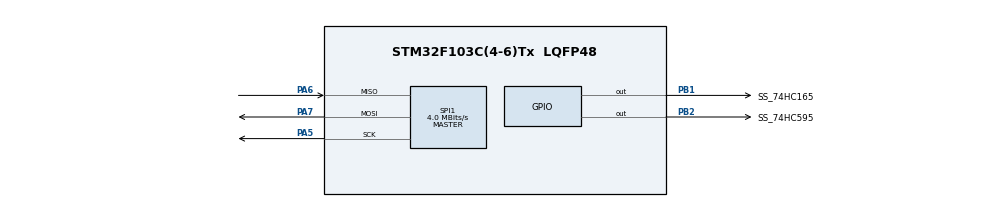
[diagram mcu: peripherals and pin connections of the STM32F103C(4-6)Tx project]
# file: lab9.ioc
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Mcu.Family=STM32F1
PA6.Mode=Full_Duplex_Master
RCC.APB2Freq_Value=8000000
PA7.Mode=Full_Duplex_Master
SPI1.Mode=SPI_MODE_MASTER
SPI1.VirtualType=VM_MASTER
PB1.GPIO_Label=SS_74HC165
Mcu.Name=STM32F103C(4-6)Tx
VP_SYS_VS_ND.Mode=No_Debug
Mcu.Package=LQFP48
PB1.Signal=GPIO_Output
PA6.Signal=SPI1_MISO
ProjectManager.StackSize=0x400
PB2.GPIO_Label=SS_74HC595
ProjectManager.HeapSize=0x200
ProjectManager.TargetToolchain=STM32CubeIDE
NVIC.PriorityGroup=NVIC_PRIORITYGROUP_4
SPI1.Direction=SPI_DIRECTION_2LINES
SPI1.CalculateBaudRate=4.0 MBits/s
RCC.APB1Freq_Value=8000000
PA5.Signal=SPI1_SCK
PB2.Signal=GPIO_Output
PA7.Signal=SPI1_MOSI
PA5.Mode=Full_Duplex_Master
board=custom

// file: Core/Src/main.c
/* USER CODE BEGIN Header */
/**
  ******************************************************************************
  * @file           : main.c
  * @brief          : Main program body
  ******************************************************************************
  * @attention
  *
  * <h2><center>&copy; Copyright (c) 2021 STMicroelectronics.
  * All rights reserved.</center></h2>
  *
  * This software component is licensed by ST under BSD 3-Clause license,
  * the "License"; You may not use this file except in compliance with the
  * License. You may obtain a copy of the License at:
  *                        opensource.org/licenses/BSD-3-Clause
  *
  ******************************************************************************
  */
/* USER CODE END Header */
#include "main.h"

SPI_HandleTypeDef hspi1;

/* USER CODE BEGIN PV */
uint8_t spi_buf[2] = {0,0};
/* USER CODE END PV */

void SystemClock_Config(void);
static void MX_GPIO_Init(void);
static void MX_SPI1_Init(void);

int main(void)
{

  /* MCU Configuration--------------------------------------------------------*/

  /* Reset of all peripherals, Initializes the Flash interface and the Systick. */
  HAL_Init();

  /* Configure the system clock */
  SystemClock_Config();

  /* Initialize all configured peripherals */
  MX_GPIO_Init();
  MX_SPI1_Init();
  /* USER CODE BEGIN 2 */
  HAL_GPIO_WritePin(SS_74HC165_GPIO_Port, SS_74HC165_Pin, GPIO_PIN_SET);
  HAL_GPIO_WritePin(SS_74HC595_GPIO_Port, SS_74HC595_Pin, GPIO_PIN_SET);

  //HAL_SPI_Transmit(&hspi1, outputBuffer, 4, 100);
  //uint8_t inputBuffer[4];
  //HAL_SPI_Receive(&hspi1, inputBuffer, 4, 100);

  /* USER CODE END 2 */

  /* Infinite loop */
  while (1)
  {
	  HAL_GPIO_WritePin(SS_74HC165_GPIO_Port, SS_74HC165_Pin, GPIO_PIN_RESET);

	  HAL_GPIO_WritePin(SS_74HC165_GPIO_Port, SS_74HC165_Pin, GPIO_PIN_SET);
	  HAL_SPI_Receive(&hspi1, (uint8_t *)spi_buf, 2, 100);

	  HAL_GPIO_WritePin(SS_74HC595_GPIO_Port, SS_74HC595_Pin, GPIO_PIN_RESET);
	  HAL_SPI_Transmit(&hspi1, (uint8_t *)spi_buf, 2, 100);
	  HAL_GPIO_WritePin(SS_74HC595_GPIO_Port, SS_74HC595_Pin, GPIO_PIN_SET);
  }
}

void SystemClock_Config(void)
{
  RCC_OscInitTypeDef RCC_OscInitStruct = {0};
  RCC_ClkInitTypeDef RCC_ClkInitStruct = {0};

  /** Initializes the RCC Oscillators according to the specified parameters
  * in the RCC_OscInitTypeDef structure.
  */
  RCC_OscInitStruct.OscillatorType = RCC_OSCILLATORTYPE_HSI;
  RCC_OscInitStruct.HSIState = RCC_HSI_ON;
  RCC_OscInitStruct.HSICalibrationValue = RCC_HSICALIBRATION_DEFAULT;
  RCC_OscInitStruct.PLL.PLLState = RCC_PLL_NONE;
  if (HAL_RCC_OscConfig(&RCC_OscInitStruct) != HAL_OK)
  {
    Error_Handler();
  }
  /** Initializes the CPU, AHB and APB buses clocks
  */
  RCC_ClkInitStruct.ClockType = RCC_CLOCKTYPE_HCLK|RCC_CLOCKTYPE_SYSCLK
                              |RCC_CLOCKTYPE_PCLK1|RCC_CLOCKTYPE_PCLK2;
  RCC_ClkInitStruct.SYSCLKSource = RCC_SYSCLKSOURCE_HSI;
  RCC_ClkInitStruct.AHBCLKDivider = RCC_SYSCLK_DIV1;
  RCC_ClkInitStruct.APB1CLKDivider = RCC_HCLK_DIV1;
  RCC_ClkInitStruct.APB2CLKDivider = RCC_HCLK_DIV1;

  if (HAL_RCC_ClockConfig(&RCC_ClkInitStruct, FLASH_LATENCY_0) != HAL_OK)
  {
    Error_Handler();
  }
}

static void MX_SPI1_Init(void)
{

  /* SPI1 parameter configuration*/
  hspi1.Instance = SPI1;
  hspi1.Init.Mode = SPI_MODE_MASTER;
  hspi1.Init.Direction = SPI_DIRECTION_2LINES;
  hspi1.Init.DataSize = SPI_DATASIZE_8BIT;
  hspi1.Init.CLKPolarity = SPI_POLARITY_LOW;
  hspi1.Init.CLKPhase = SPI_PHASE_1EDGE;
  hspi1.Init.NSS = SPI_NSS_SOFT;
  hspi1.Init.BaudRatePrescaler = SPI_BAUDRATEPRESCALER_2;
  hspi1.Init.FirstBit = SPI_FIRSTBIT_MSB;
  hspi1.Init.TIMode = SPI_TIMODE_DISABLE;
  hspi1.Init.CRCCalculation = SPI_CRCCALCULATION_DISABLE;
  hspi1.Init.CRCPolynomial = 10;
  if (HAL_SPI_Init(&hspi1) != HAL_OK)
  {
    Error_Handler();
  }

}

static void MX_GPIO_Init(void)
{
  GPIO_InitTypeDef GPIO_InitStruct = {0};

  /* GPIO Ports Clock Enable */
  __HAL_RCC_GPIOA_CLK_ENABLE();
  __HAL_RCC_GPIOB_CLK_ENABLE();

  /*Configure GPIO pin Output Level */
  HAL_GPIO_WritePin(GPIOB, SS_74HC165_Pin|SS_74HC595_Pin, GPIO_PIN_RESET);

  /*Configure GPIO pins : SS_74HC165_Pin SS_74HC595_Pin */
  GPIO_InitStruct.Pin = SS_74HC165_Pin|SS_74HC595_Pin;
  GPIO_InitStruct.Mode = GPIO_MODE_OUTPUT_PP;
  GPIO_InitStruct.Pull = GPIO_NOPULL;
  GPIO_InitStruct.Speed = GPIO_SPEED_FREQ_LOW;
  HAL_GPIO_Init(GPIOB, &GPIO_InitStruct);

}

void Error_Handler(void)
{
  __disable_irq();
  while (1)
  {
  }
}

/************************ (C) COPYRIGHT STMicroelectronics *****END OF FILE****/
